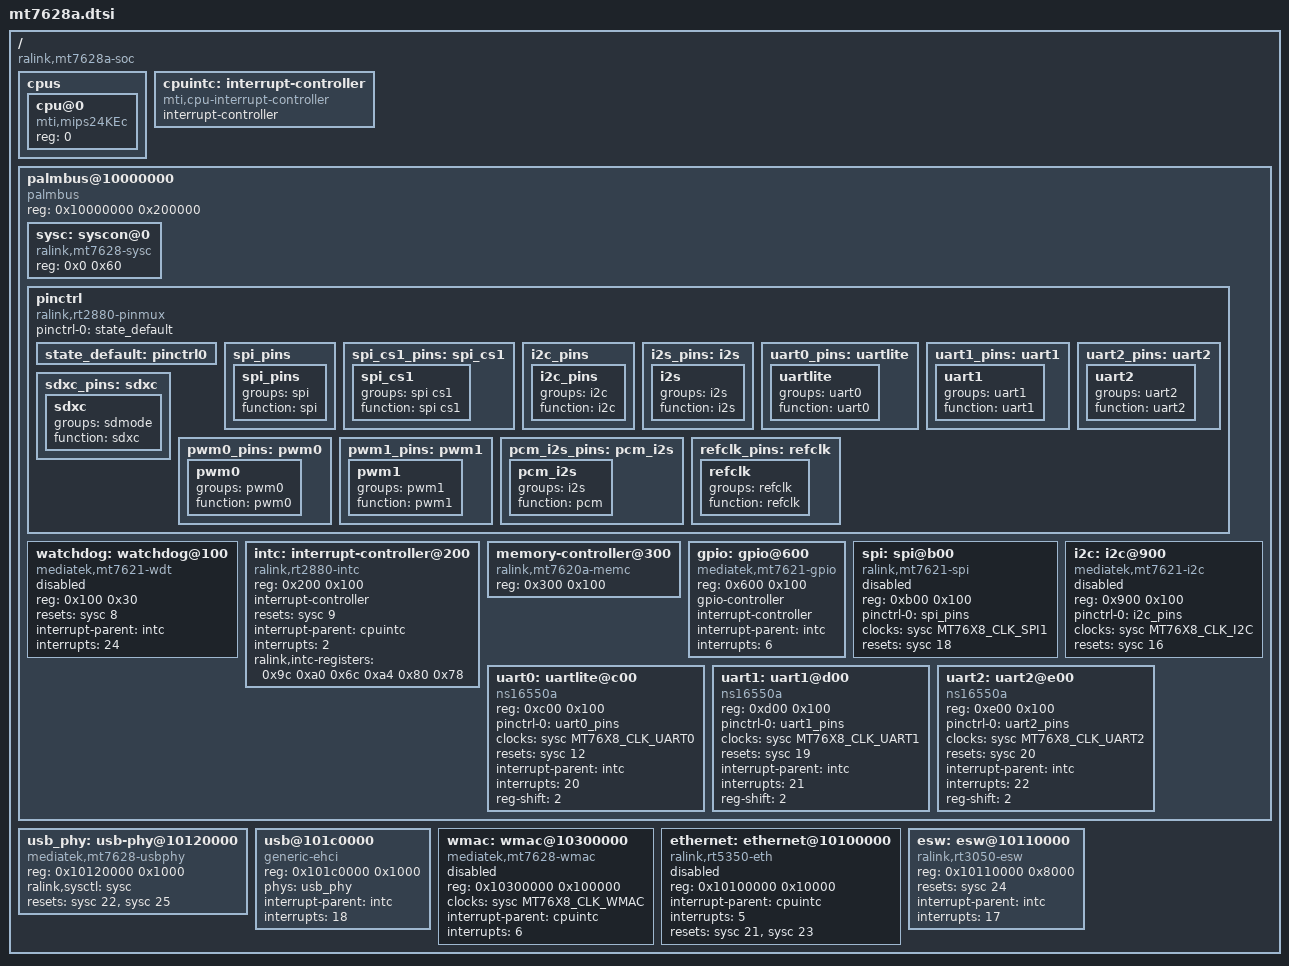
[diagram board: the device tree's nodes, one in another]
// SPDX-License-Identifier: GPL-2.0
#include <dt-bindings/clock/mediatek,mtmips-sysc.h>

/ {
	#address-cells = <1>;
	#size-cells = <1>;
	compatible = "ralink,mt7628a-soc";

	cpus {
		#address-cells = <1>;
		#size-cells = <0>;

		cpu@0 {
			compatible = "mti,mips24KEc";
			device_type = "cpu";
			reg = <0>;
		};
	};

	cpuintc: interrupt-controller {
		#address-cells = <0>;
		#interrupt-cells = <1>;
		interrupt-controller;
		compatible = "mti,cpu-interrupt-controller";
	};

	palmbus@10000000 {
		compatible = "palmbus";
		reg = <0x10000000 0x200000>;
		ranges = <0x0 0x10000000 0x1FFFFF>;

		#address-cells = <1>;
		#size-cells = <1>;

		sysc: syscon@0 {
			compatible = "ralink,mt7628-sysc", "syscon";
			reg = <0x0 0x60>;
			#clock-cells = <1>;
			#reset-cells = <1>;
		};

		pinctrl: pinctrl {
			compatible = "ralink,rt2880-pinmux";
			pinctrl-names = "default";
			pinctrl-0 = <&state_default>;
	
			state_default: pinctrl0 {
			};
	
			spi_pins: spi_pins {
				spi_pins {
					groups = "spi";
					function = "spi";
				};
			};
	
			spi_cs1_pins: spi_cs1 {
				spi_cs1 {
					groups = "spi cs1";
					function = "spi cs1";
				};
			};
	
			i2c_pins: i2c_pins {
				i2c_pins {
					groups = "i2c";
					function = "i2c";
				};
			};
	
			i2s_pins: i2s {
				i2s {
					groups = "i2s";
					function = "i2s";
				};
			};
	
			uart0_pins: uartlite {
				uartlite {
					groups = "uart0";
					function = "uart0";
				};
			};
	
			uart1_pins: uart1 {
				uart1 {
					groups = "uart1";
					function = "uart1";
				};
			};
	
			uart2_pins: uart2 {
				uart2 {
					groups = "uart2";
					function = "uart2";
				};
			};
	
			sdxc_pins: sdxc {
				sdxc {
					groups = "sdmode";
					function = "sdxc";
				};
			};
	
			pwm0_pins: pwm0 {
				pwm0 {
					groups = "pwm0";
					function = "pwm0";
				};
			};
	
			pwm1_pins: pwm1 {
				pwm1 {
					groups = "pwm1";
					function = "pwm1";
				};
			};
	
			pcm_i2s_pins: pcm_i2s {
				pcm_i2s {
					groups = "i2s";
					function = "pcm";
				};
			};
	
			refclk_pins: refclk {
				refclk {
					groups = "refclk";
					function = "refclk";
				};
			};
		};

		watchdog: watchdog@100 {
			compatible = "mediatek,mt7621-wdt";
			reg = <0x100 0x30>;

			resets = <&sysc 8>;
			reset-names = "wdt";

			interrupt-parent = <&intc>;
			interrupts = <24>;

			status = "disabled";
		};

		intc: interrupt-controller@200 {
			compatible = "ralink,rt2880-intc";
			reg = <0x200 0x100>;

			interrupt-controller;
			#interrupt-cells = <1>;

			resets = <&sysc 9>;
			reset-names = "intc";

			interrupt-parent = <&cpuintc>;
			interrupts = <2>;

			ralink,intc-registers = <0x9c 0xa0
						 0x6c 0xa4
						 0x80 0x78>;
		};

		memory-controller@300 {
			compatible = "ralink,mt7620a-memc";
			reg = <0x300 0x100>;
		};

		gpio: gpio@600 {
			compatible = "mediatek,mt7621-gpio";
			reg = <0x600 0x100>;

			gpio-controller;
			interrupt-controller;
			#gpio-cells = <2>;
			#interrupt-cells = <2>;

			interrupt-parent = <&intc>;
			interrupts = <6>;
		};

		spi: spi@b00 {
			compatible = "ralink,mt7621-spi";
			reg = <0xb00 0x100>;

			pinctrl-names = "default";
			pinctrl-0 = <&spi_pins>;

			clocks = <&sysc MT76X8_CLK_SPI1>;

			resets = <&sysc 18>;
			reset-names = "spi";

			#address-cells = <1>;
			#size-cells = <0>;

			status = "disabled";
		};

		i2c: i2c@900 {
			compatible = "mediatek,mt7621-i2c";
			reg = <0x900 0x100>;

			pinctrl-names = "default";
			pinctrl-0 = <&i2c_pins>;

			clocks = <&sysc MT76X8_CLK_I2C>;

			resets = <&sysc 16>;
			reset-names = "i2c";

			#address-cells = <1>;
			#size-cells = <0>;

			status = "disabled";
		};

		uart0: uartlite@c00 {
			compatible = "ns16550a";
			reg = <0xc00 0x100>;

			pinctrl-names = "default";
			pinctrl-0 = <&uart0_pins>;

			clocks = <&sysc MT76X8_CLK_UART0>;

			resets = <&sysc 12>;
			reset-names = "uart0";

			interrupt-parent = <&intc>;
			interrupts = <20>;

			reg-shift = <2>;
		};

		uart1: uart1@d00 {
			compatible = "ns16550a";
			reg = <0xd00 0x100>;

			pinctrl-names = "default";
			pinctrl-0 = <&uart1_pins>;

			clocks = <&sysc MT76X8_CLK_UART1>;

			resets = <&sysc 19>;
			reset-names = "uart1";

			interrupt-parent = <&intc>;
			interrupts = <21>;

			reg-shift = <2>;
		};

		uart2: uart2@e00 {
			compatible = "ns16550a";
			reg = <0xe00 0x100>;

			pinctrl-names = "default";
			pinctrl-0 = <&uart2_pins>;

			clocks = <&sysc MT76X8_CLK_UART2>;

			resets = <&sysc 20>;
			reset-names = "uart2";

			interrupt-parent = <&intc>;
			interrupts = <22>;

			reg-shift = <2>;
		};
	};

	usb_phy: usb-phy@10120000 {
		compatible = "mediatek,mt7628-usbphy";
		reg = <0x10120000 0x1000>;

		#phy-cells = <0>;

		ralink,sysctl = <&sysc>;
		resets = <&sysc 22 &sysc 25>;
		reset-names = "host", "device";
	};

	usb@101c0000 {
		compatible = "generic-ehci";
		reg = <0x101c0000 0x1000>;

		phys = <&usb_phy>;
		phy-names = "usb";

		interrupt-parent = <&intc>;
		interrupts = <18>;
	};

	wmac: wmac@10300000 {
		compatible = "mediatek,mt7628-wmac";
		reg = <0x10300000 0x100000>;

		clocks = <&sysc MT76X8_CLK_WMAC>;

		interrupt-parent = <&cpuintc>;
		interrupts = <6>;

		status = "disabled";
	};

	ethernet: ethernet@10100000 {
		compatible = "ralink,rt5350-eth";
		reg = <0x10100000 0x10000>;

		#address-cells = <1>;
		#size-cells = <0>;

		interrupt-parent = <&cpuintc>;
		interrupts = <5>;

		resets = <&sysc 21>, <&sysc 23>;
		reset-names = "fe", "esw";

		status = "disabled";
	};

	esw: esw@10110000 {
		compatible = "ralink,rt3050-esw";
		reg = <0x10110000 0x8000>;

		resets = <&sysc 24>;
		reset-names = "ephy";

		interrupt-parent = <&intc>;
		interrupts = <17>;
	};
};
